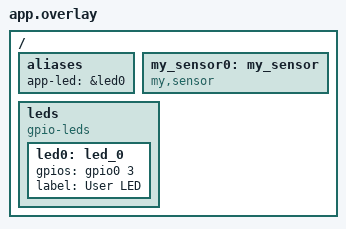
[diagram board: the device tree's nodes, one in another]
/ {
    aliases {
            app-led = &led0;
        };
    my_sensor0: my_sensor {
        compatible = "my,sensor";
        status = "okay";
    };

    // i have created  the node led0 
    // since i am using esp32c3-devkitm, doesn't have a built-int LED, 
    //mapped with a node named "led0" 
    leds {
        compatible = "gpio-leds";
        led0: led_0  {
            gpios = <&gpio0 3 GPIO_ACTIVE_HIGH>;
            label = "User LED";
        };
    };
};
